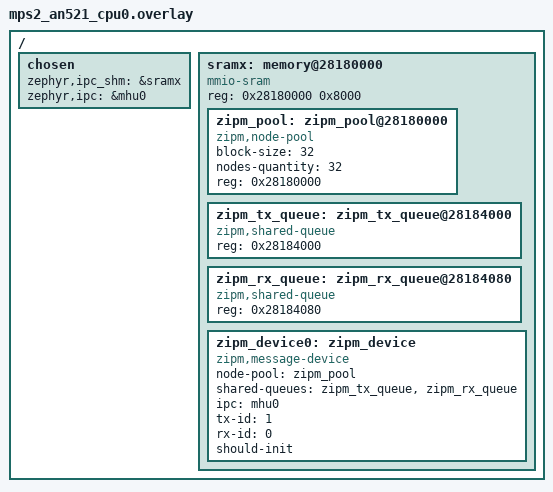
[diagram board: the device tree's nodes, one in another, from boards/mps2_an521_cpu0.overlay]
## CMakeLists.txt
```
# Copyright 2024 Felipe Neves
#
# SPDX-License-Identifier: Apache-2.0
#

cmake_minimum_required(VERSION 3.20.0)

find_package(Zephyr REQUIRED HINTS $ENV{ZEPHYR_BASE})
project(zipm_test)
enable_language(C ASM)
target_sources(app PRIVATE src/main.c)
```

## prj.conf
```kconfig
CONFIG_PRINTK=y
CONFIG_ZIPM=y
CONFIG_ZTEST=y
CONFIG_MBOX=y
```

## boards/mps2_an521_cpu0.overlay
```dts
/*
 * Copyright (c) 2024 Felipe Neves
 *
 * SPDX-License-Identifier: Apache-2.0
 */
/ {
	chosen {
		zephyr,ipc_shm = &sramx;
		zephyr,ipc = &mhu0;
	};
	
	sramx: memory@28180000 {
		compatible = "mmio-sram";
		reg = <0x28180000 0x8000>;
	};
};

&sramx {
	#address-cells = <1>;
	#size-cells = <0>;
  
	zipm_pool: zipm_pool@28180000 {
		compatible = "zipm,node-pool";
		block-size = <32>;
		nodes-quantity = <32>;
		reg = <0x28180000>;
	};

	zipm_tx_queue: zipm_tx_queue@28184000 {
		compatible = "zipm,shared-queue";
		reg = <0x28184000>;
	};
  
	zipm_rx_queue: zipm_rx_queue@28184080 {
		compatible = "zipm,shared-queue";
		reg = <0x28184080>;
	};

	zipm_device0: zipm_device {
        compatible = "zipm,message-device";
        status = "okay";
        node-pool = <&zipm_pool>;
        shared-queues = <&zipm_tx_queue &zipm_rx_queue>;
        ipc = <&mhu0>;
		tx-id = <1>;
		rx-id = <0>;
		should-init;
    };
};
```

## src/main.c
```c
/*
 * Copyright (c) 2024 Felipe Neves
 *
 * SPDX-License-Identifier: Apache-2.0
 */

#include <stdio.h>
#include <stdlib.h>
#include <string.h>
#include <zephyr/kernel.h>
#include <zephyr/device.h>
#include <zipm/zipm.h>
#include <zephyr/ztest.h>

void zipm_event_callback(const struct device *dev, int shared_queue_number, void *user_data)
{
}

static void zipm_tests_before(void *f)
{
}

static void zipm_tests_after(void *f)
{
}

ZTEST(zipm_test_suite, zipm_initialise_handler)
{
	const struct device *handle = DEVICE_DT_GET(DT_NODELABEL(zipm_device0));
	struct zipm_callback callback; 

	zassert_equal(zipm_register_event_callback(handle, &callback,
				 zipm_event_callback, NULL), 0);
	zassert_equal(callback.callback, &zipm_event_callback);
	zassert_equal(callback.user_data, &callback);
	zassert_equal(zipm_remove_event_callback(handle,&callback), 0);
}

ZTEST(zipm_test_suite, send_receive)
{
	uint8_t data[] = {'Z','I','P','M'};
	uint8_t rx_data[] = {0,0,0,0};
	size_t rx_size = 0;

	const struct device *handle = DEVICE_DT_GET(DT_NODELABEL(zipm_device0));
	struct zipm_callback callback; 

	zassert_equal(zipm_register_event_callback(handle, &callback,
				 zipm_event_callback, NULL), 0);
	zassert_equal(callback.callback, &zipm_event_callback);
	zassert_equal(callback.user_data, &callback);

	zassert_equal(zipm_send(handle, &data, sizeof(data), 0, 0), 0);
	zassert_equal(zipm_receive(handle, &rx_data, rx_size, 0), 0);
	zassert_equal(rx_size, sizeof(data));
	zassert_equal(memcmp(data, rx_data, sizeof(rx_data)), 0);
	zassert_equal(zipm_flush(handle, 0), 0);
	zassert_equal(zipm_remove_event_callback(handle,&callback), 0);
}

ZTEST(zipm_test_suite, send_exaust_memory)
{
	uint8_t data[] = {'Z','I','P','M'};
	uint8_t rx_data[] = {0,0,0,0};
	size_t rx_size = 0;
	int err = 0;

	const struct device *handle = DEVICE_DT_GET(DT_NODELABEL(zipm_device0));
	struct zipm_callback callback; 

	zassert_equal(zipm_register_event_callback(handle, &callback,
				 zipm_event_callback, NULL), 0);
	zassert_equal(callback.callback, &zipm_event_callback);
	zassert_equal(callback.user_data, &callback);

	do {
		err = zipm_send(handle, &data, sizeof(data), 0, 0);
	} while(!err);

	err = 0;

	do {
		err = zipm_receive(handle, &rx_data, rx_size, 0);
		if(!err) {
			zassert_equal(rx_size, sizeof(data));
			zassert_equal(memcmp(data, rx_data, sizeof(rx_data)), 0);
		}
	} while(!err);

	zassert_equal(zipm_flush(handle, 0), 0);
	zassert_equal(zipm_remove_event_callback(handle,&callback), 0);
}

ZTEST_SUITE(zipm_test_suite, NULL, NULL, zipm_tests_before, zipm_tests_after, NULL);
```
